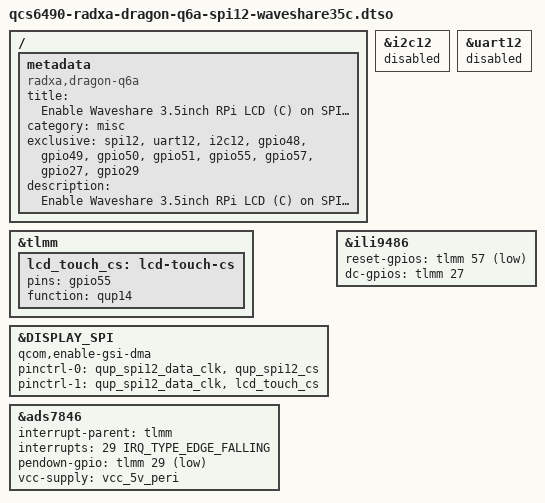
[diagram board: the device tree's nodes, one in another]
// SPDX-License-Identifier: BSD-3-Clause
/*
 * Copyright (c) 2025 Radxa Computer (Shenzhen) Co., Ltd.
 */

/dts-v1/;
/plugin/;

#define DISPLAY_SPI spi12
#include "waveshare35-lcd.dtsi"

/ {
    metadata {
        title = "Enable Waveshare 3.5inch RPi LCD (C) on SPI12";
        compatible = "radxa,dragon-q6a";
        category = "misc";
        exclusive = "spi12", "uart12", "i2c12", "gpio48", "gpio49", "gpio50", "gpio51", "gpio55", "gpio57", "gpio27", "gpio29";
        description = "Enable Waveshare 3.5inch RPi LCD (C) on SPI12.";
    };
};

&tlmm {	
	lcd_touch_cs: lcd-touch-cs {
		pins = "gpio55";
		function = "qup14";
	};
};

&i2c12 {
	status = "disabled";
};

&uart12 {
	status = "disabled";
};

&DISPLAY_SPI {
	qcom,enable-gsi-dma;
	status = "okay";
	pinctrl-0 = <&qup_spi12_data_clk>, <&qup_spi12_cs>;
	pinctrl-1 = <&qup_spi12_data_clk>, <&lcd_touch_cs>;
};

&ili9486 {
	reset-gpios = <&tlmm 57 GPIO_ACTIVE_LOW>;
	dc-gpios = <&tlmm 27 GPIO_ACTIVE_HIGH>;
};

&ads7846 {
	interrupt-parent = <&tlmm>;
	interrupts = <29 IRQ_TYPE_EDGE_FALLING>;
	pendown-gpio = <&tlmm 29 GPIO_ACTIVE_LOW>;
	vcc-supply = <&vcc_5v_peri>;
};
